# STM32F103T6U6 register map
File version: 1.0
Registers are 32-bit, access not given, reset 0x0 unless marked. A register's access mark holds for its fields unless they carry their own. Offsets are from the block's base; [hi:lo] are bit positions; {n}, {i} and the like mark numbered series; 'fields as' and 'values as' point back to an identical list.

## SPI1
Base 0x40013000
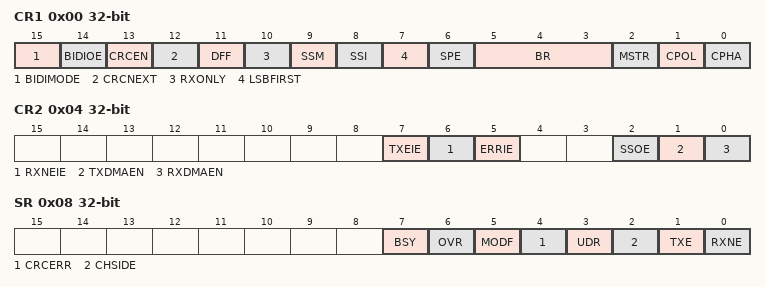
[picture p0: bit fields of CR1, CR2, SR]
0x00 CR1
  [15] BIDIMODE, [14] BIDIOE, [13] CRCEN, [12] CRCNEXT, [11] DFF, [10] RXONLY, [9] SSM, [8] SSI, [7] LSBFIRST, [6] SPE, [5:3] BR, [2] MSTR, [1] CPOL, [0] CPHA
0x04 CR2
  [7] TXEIE, [6] RXNEIE, [5] ERRIE, [2] SSOE, [1] TXDMAEN, [0] RXDMAEN
0x08 SR
  [7] BSY, [6] OVR, [5] MODF, [4] CRCERR, [3] UDR, [2] CHSIDE, [1] TXE, [0] RXNE
0x0C DR
  [15:0] DR
0x10 CRCPR
  [15:0] CRCPOLY
0x14 RXCRCR
  [15:0] RXCRC
0x18 TXCRCR
  [15:0] TXCRC
0x1C I2SCFGR
  [11] I2SMOD

## DMA1
Base 0x40020000
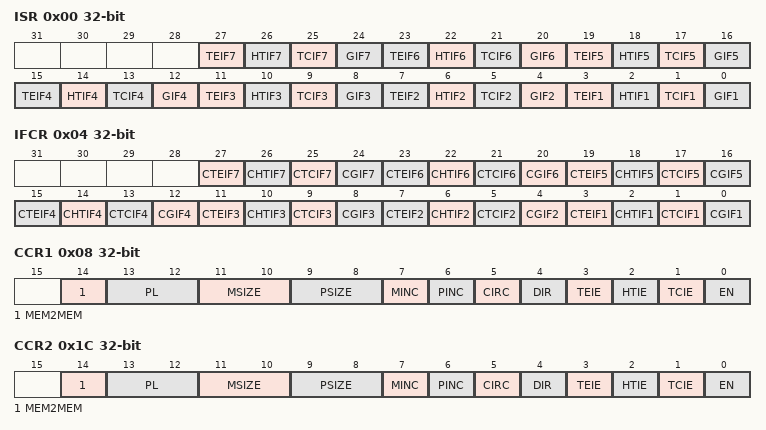
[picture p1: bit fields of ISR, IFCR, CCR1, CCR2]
0x00 ISR
  [4n-1] TEIF{n} (n=1..7), [4n-2] HTIF{n} (n=1..7), [4n-3] TCIF{n} (n=1..7), [4n-4] GIF{n} (n=1..7)
0x04 IFCR
  [4n-1] CTEIF{n} (n=1..7), [4n-2] CHTIF{n} (n=1..7), [4n-3] CTCIF{n} (n=1..7), [4n-4] CGIF{n} (n=1..7)
0x08 CCR1
  [14] MEM2MEM, [13:12] PL, [11:10] MSIZE, [9:8] PSIZE, [7] MINC, [6] PINC, [5] CIRC, [4] DIR, [3] TEIE, [2] HTIE, [1] TCIE, [0] EN
0x0C CNDTR1
  [15:0] NDT
0x10 CPAR1
  [31:0] PA
{0x0+0x14*i} CMAR{i} (i=1..7)
  [31:0] MA
0x1C CCR2
  fields as CCR1
0x20 CNDTR2
  [15:0] NDT
0x24 CPAR2
  [31:0] PA
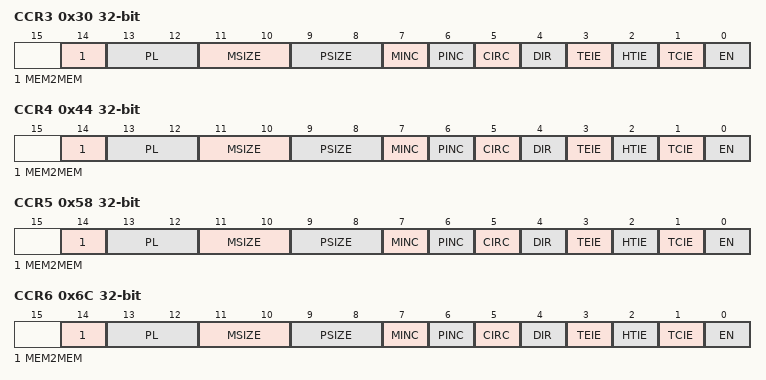
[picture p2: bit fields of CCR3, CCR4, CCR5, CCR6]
0x30 CCR3
  fields as CCR1
0x34 CNDTR3
  [15:0] NDT
0x38 CPAR3
  [31:0] PA
0x44 CCR4
  fields as CCR1
0x48 CNDTR4
  [15:0] NDT
0x4C CPAR4
  [31:0] PA
0x58 CCR5
  fields as CCR1
0x5C CNDTR5
  [15:0] NDT
0x60 CPAR5
  [31:0] PA
0x6C CCR6
  fields as CCR1
0x70 CNDTR6
  [15:0] NDT
0x74 CPAR6
  [31:0] PA
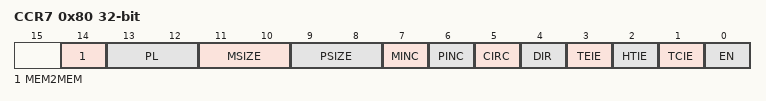
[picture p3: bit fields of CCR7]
0x80 CCR7
  fields as CCR1
0x84 CNDTR7
  [15:0] NDT
0x88 CPAR7
  [31:0] PA

## RCC
Base 0x40021000
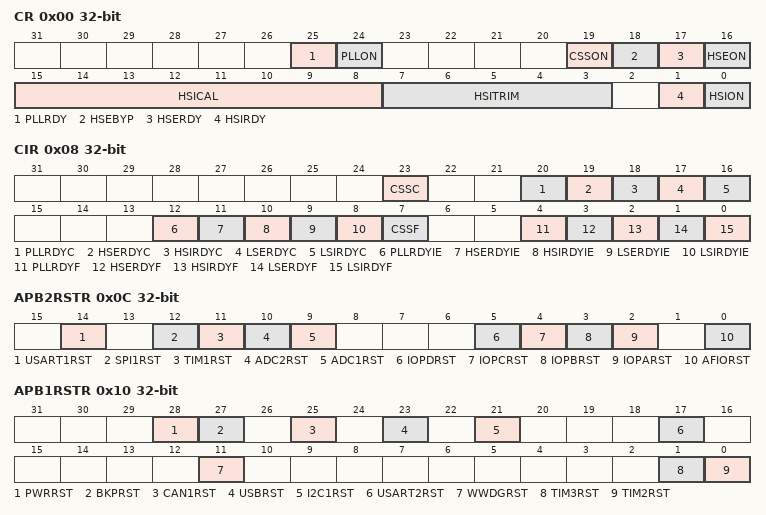
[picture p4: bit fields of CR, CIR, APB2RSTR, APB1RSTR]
0x00 CR
  [25] PLLRDY, [24] PLLON, [19] CSSON, [18] HSEBYP, [17] HSERDY, [16] HSEON, [15:8] HSICAL, [7:3] HSITRIM, [1] HSIRDY, [0] HSION
0x04 CFGR
  [26:24] MCO, [22] USBPRE, [21] PLLMULL10, [20] PLLMULL6, [20:19] PLLMULL8, [20:18] PLLMULL9, [17] PLLXTPRE, [16] PLLSRC, [15:14] ADCPRE, [13:11] PPRE2, [10:8] PPRE1, [7:4] HPRE, [3:2] SWS, [1:0] SW
0x08 CIR
  [23] CSSC, [20] PLLRDYC, [19] HSERDYC, [18] HSIRDYC, [17] LSERDYC, [16] LSIRDYC, [12] PLLRDYIE, [11] HSERDYIE, [10] HSIRDYIE, [9] LSERDYIE, [8] LSIRDYIE, [7] CSSF, [4] PLLRDYF, [3] HSERDYF, [2] HSIRDYF, [1] LSERDYF, [0] LSIRDYF
0x0C APB2RSTR
  [14] USART1RST, [12] SPI1RST, [11] TIM1RST, [10] ADC2RST, [9] ADC1RST, [5] IOPDRST, [4] IOPCRST, [3] IOPBRST, [2] IOPARST, [0] AFIORST
0x10 APB1RSTR
  [28] PWRRST, [27] BKPRST, [25] CAN1RST, [23] USBRST, [21] I2C1RST, [17] USART2RST, [11] WWDGRST, [1] TIM3RST, [0] TIM2RST
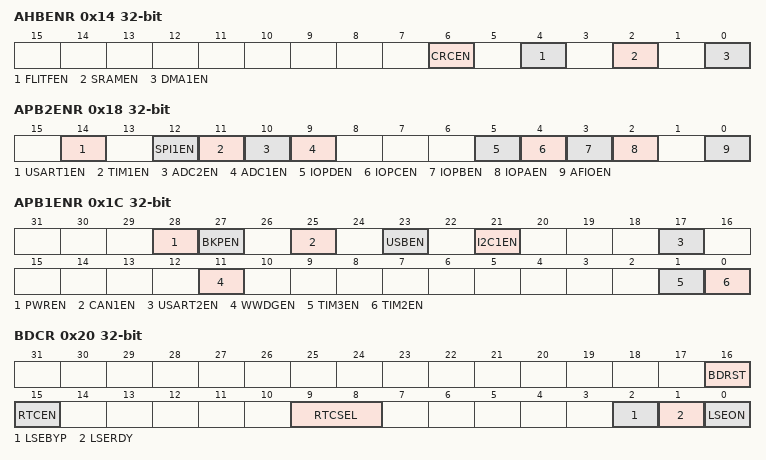
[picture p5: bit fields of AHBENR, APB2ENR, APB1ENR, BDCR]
0x14 AHBENR
  [6] CRCEN, [4] FLITFEN, [2] SRAMEN, [0] DMA1EN
0x18 APB2ENR
  [14] USART1EN, [12] SPI1EN, [11] TIM1EN, [10] ADC2EN, [9] ADC1EN, [5] IOPDEN, [4] IOPCEN, [3] IOPBEN, [2] IOPAEN, [0] AFIOEN
0x1C APB1ENR
  [28] PWREN, [27] BKPEN, [25] CAN1EN, [23] USBEN, [21] I2C1EN, [17] USART2EN, [11] WWDGEN, [1] TIM3EN, [0] TIM2EN
0x20 BDCR
  [16] BDRST, [15] RTCEN, [9:8] RTCSEL, [2] LSEBYP, [1] LSERDY, [0] LSEON
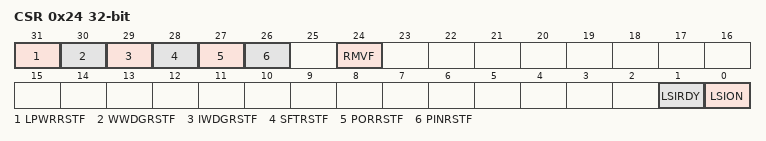
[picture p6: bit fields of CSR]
0x24 CSR
  [31] LPWRRSTF, [30] WWDGRSTF, [29] IWDGRSTF, [28] SFTRSTF, [27] PORRSTF, [26] PINRSTF, [24] RMVF, [1] LSIRDY, [0] LSION

## FLASH
Base 0x40022000
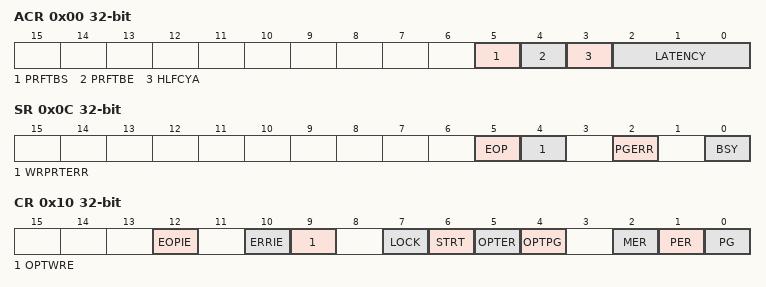
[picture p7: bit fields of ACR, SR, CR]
0x00 ACR
  [5] PRFTBS, [4] PRFTBE, [3] HLFCYA, [2:0] LATENCY
0x04 KEYR
  [31:0] FKEYR
0x08 OPTKEYR
0x0C SR
  [5] EOP, [4] WRPRTERR, [2] PGERR, [0] BSY
0x10 CR
  [12] EOPIE, [10] ERRIE, [9] OPTWRE, [7] LOCK, [6] STRT, [5] OPTER, [4] OPTPG, [2] MER, [1] PER, [0] PG
0x14 AR
  [31:0] FAR
0x1C OBR
  [25:18] DATA1, [17:10] DATA0, [4] nRST_STDBY, [3] nRST_STOP, [4:2] USER, [1] RDPRT, [0] OPTERR
0x20 WRPR
  [31:0] WRP

## CRC
Base 0x40023000
0x00 DR
0x04 IDR 8-bit
0x08 CR
  [0] RESET

## DBGMCU
Base 0xE0042000
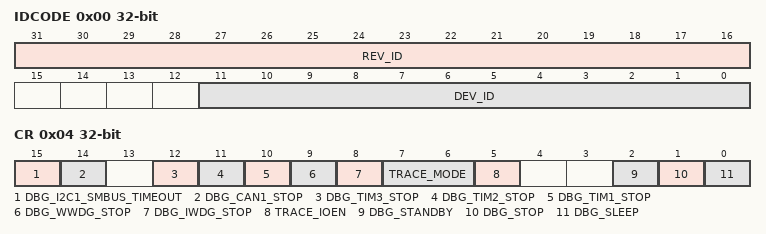
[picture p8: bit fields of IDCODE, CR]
0x00 IDCODE
  [31:16] REV_ID, [11:0] DEV_ID
0x04 CR
  [15] DBG_I2C1_SMBUS_TIMEOUT, [14] DBG_CAN1_STOP, [12] DBG_TIM3_STOP, [11] DBG_TIM2_STOP, [10] DBG_TIM1_STOP, [9] DBG_WWDG_STOP, [8] DBG_IWDG_STOP, [7:6] TRACE_MODE, [5] TRACE_IOEN, [2] DBG_STANDBY, [1] DBG_STOP, [0] DBG_SLEEP
